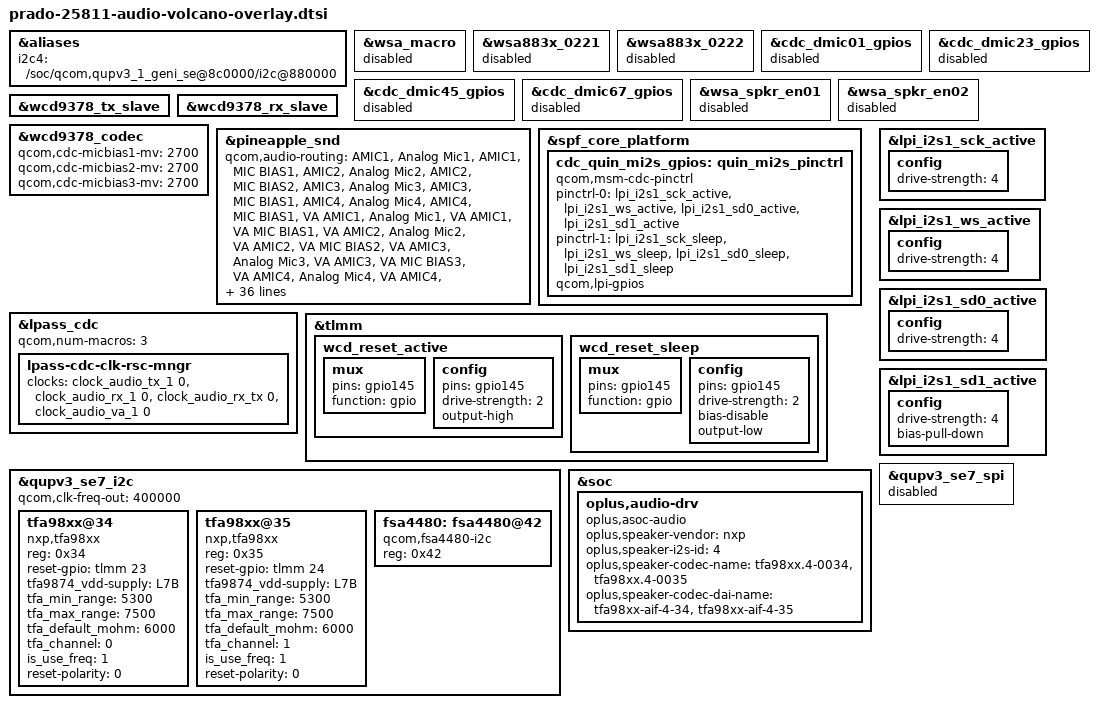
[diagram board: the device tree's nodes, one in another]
&aliases {
	i2c4 = "/soc/qcom,qupv3_1_geni_se@8c0000/i2c@880000";
};

&wsa_macro{
	status = "disabled";
};

&wsa883x_0221{
	status = "disabled";
};

&wsa883x_0222{
	status = "disabled";
};

&cdc_dmic01_gpios{
	status = "disabled";
};

&cdc_dmic23_gpios{
	status = "disabled";
};

&cdc_dmic45_gpios{
	status = "disabled";
};

&cdc_dmic67_gpios{
	status = "disabled";
};

&wsa_spkr_en01{
	status = "disabled";
};

&wsa_spkr_en02{
	status = "disabled";
};

&wcd9378_tx_slave{
	status = "okay";
};

&wcd9378_rx_slave{
	status = "okay";
};

&wcd9378_codec{
	status = "okay";
	qcom,cdc-micbias1-mv = <2700>;
	qcom,cdc-micbias2-mv = <2700>;
	qcom,cdc-micbias3-mv = <2700>;
};

&pineapple_snd{
    qcom,audio-routing =
		"AMIC1", "Analog Mic1",
		"AMIC1", "MIC BIAS1",
		"AMIC2", "Analog Mic2",
		"AMIC2", "MIC BIAS2",
		"AMIC3", "Analog Mic3",
		"AMIC3", "MIC BIAS1",
		"AMIC4", "Analog Mic4",
		"AMIC4", "MIC BIAS1",
		"VA AMIC1", "Analog Mic1",
		"VA AMIC1", "VA MIC BIAS1",
		"VA AMIC2", "Analog Mic2",
		"VA AMIC2", "VA MIC BIAS2",
		"VA AMIC3", "Analog Mic3",
		"VA AMIC3", "VA MIC BIAS3",
		"VA AMIC4", "Analog Mic4",
		"VA AMIC4", "VA MIC BIAS1",
		"TX DMIC0", "Digital Mic0",
		"TX DMIC0", "MIC BIAS3",
		"TX DMIC1", "Digital Mic1",
		"TX DMIC1", "MIC BIAS3",
		"TX DMIC2", "Digital Mic2",
		"TX DMIC2", "MIC BIAS1",
		"TX DMIC3", "Digital Mic3",
		"TX DMIC3", "MIC BIAS1",
		"IN1_HPHL", "HPHL_OUT",
		"IN2_HPHR", "HPHR_OUT",
		"IN3_AUX", "AUX_OUT",
		"RX_TX DEC0_INP", "TX DEC0 MUX",
		"RX_TX DEC1_INP", "TX DEC1 MUX",
		"RX_TX DEC2_INP", "TX DEC2 MUX",
		"RX_TX DEC3_INP", "TX DEC3 MUX",
		"VA SWR_INPUT", "VA_SWR_CLK",
		"VA_AIF1 CAP", "VA_SWR_CLK",
		"VA_AIF2 CAP", "VA_SWR_CLK",
		"VA_AIF3 CAP", "VA_SWR_CLK",
		"VA DMIC0", "Digital Mic0",
		"VA DMIC1", "Digital Mic1",
		"VA DMIC2", "Digital Mic2",
		"VA DMIC3", "Digital Mic3",
		"VA DMIC0", "VA MIC BIAS3",
		"VA DMIC1", "VA MIC BIAS3",
		"VA DMIC2", "VA MIC BIAS1",
		"VA DMIC3", "VA MIC BIAS1";
	asoc-codec  = <&stub_codec>, <&lpass_cdc>,
		<&wcd9378_codec>;
	asoc-codec-names = "msm-stub-codec.1", "lpass-cdc",
		"wcd9378_codec";
	qcom,wsa-max-devs = <0>;
	qcom,mi2s-audio-intf = <1>;
	qcom,tdm-audio-intf = <0>;
	qcom,quin-mi2s-gpios = <&cdc_quin_mi2s_gpios>;
	swr-haptics-unsupported; // disable qcom haptics
	qcom,wcn-bt = <1>;
	qcom,ext-disp-audio-rx = <1>;

	qcom,msm-mbhc-usbc-audio-supported = <1>;
	qcom,msm-mbhc-hs-mic-max-threshold-mv = <2600>;
	qcom,msm-mbhc-hs-mic-min-threshold-mv = <112>;/* 75*2700/1800 */
	qcom,msm-mbhc-hphl-swh = <0>;
	qcom,msm-mbhc-gnd-swh = <0>;
	oplus,mbhc-headset-micbias-alwayon = <1>;
	oplus,mbhc-check-cross-conn = <1>;

	fsa4480-i2c-handle = <&fsa4480>;
};

&spf_core_platform {
	cdc_quin_mi2s_gpios: quin_mi2s_pinctrl {
		status = "ok";
		compatible = "qcom,msm-cdc-pinctrl";
		pinctrl-names = "aud_active", "aud_sleep";
		pinctrl-0 = <&lpi_i2s1_sck_active &lpi_i2s1_ws_active
				&lpi_i2s1_sd0_active &lpi_i2s1_sd1_active>;
		pinctrl-1 = <&lpi_i2s1_sck_sleep &lpi_i2s1_ws_sleep
				&lpi_i2s1_sd0_sleep &lpi_i2s1_sd1_sleep>;
		qcom,lpi-gpios;
		#gpio-cells = <0>;
	};
};

&lpass_cdc {
	qcom,num-macros = <3>;
	lpass-cdc-clk-rsc-mngr {
		clock-names = "tx_core_clk", "rx_core_clk", "rx_tx_core_clk", "va_core_clk";
		clocks = <&clock_audio_tx_1 0>, <&clock_audio_rx_1 0>,
			<&clock_audio_rx_tx 0>, <&clock_audio_va_1 0>;
	};
};

&tlmm {
	/* WCD reset pin */
	wcd_reset_active: wcd_reset_active {
		mux {
			pins = "gpio145";
			function = "gpio";
		};

		config {
			pins = "gpio145";
			drive-strength = <2>;
			output-high;
		};
	};

	wcd_reset_sleep: wcd_reset_sleep {
		mux {
			pins = "gpio145";
			function = "gpio";
		};

		config {
			pins = "gpio145";
			drive-strength = <2>;
			bias-disable;
			output-low;
		};
	};
};

&qupv3_se7_i2c {
	status = "ok";
	qcom,clk-freq-out = <400000>;
	tfa98xx@34 {
		compatible = "nxp,tfa98xx";
		reg = <0x34>;
		reset-gpio = <&tlmm 23 0x00>;
		tfa9874_vdd-supply = <&L7B>;
		tfa_min_range = <5300>;
		tfa_max_range = <7500>;
		tfa_default_mohm = <6000>;
		tfa_channel = <0>;
		is_use_freq = <1>;
		reset-polarity = <0>;
		status = "ok";
	};
	tfa98xx@35 {
		compatible = "nxp,tfa98xx";
		reg = <0x35>;
		reset-gpio = <&tlmm 24 0x00>;
		tfa9874_vdd-supply = <&L7B>;
		tfa_min_range = <5300>;
		tfa_max_range = <7500>;
		tfa_default_mohm = <6000>;
		tfa_channel = <1>;
		is_use_freq = <1>;
		reset-polarity = <0>;
		status = "ok";
	};

	fsa4480: fsa4480@42 {
		status = "ok";
		compatible = "qcom,fsa4480-i2c";
		reg = <0x42>;
	};
};

&soc {
	oplus,audio-drv {
		compatible = "oplus,asoc-audio";
		//for nxp speaker
		oplus,speaker-vendor = "nxp";
		oplus,speaker-i2s-id = <4>;
		oplus,speaker-codec-name = "tfa98xx.4-0034", "tfa98xx.4-0035";
		oplus,speaker-codec-dai-name = "tfa98xx-aif-4-34", "tfa98xx-aif-4-35";
	};
};

&lpi_i2s1_sck_active {
	config {
		drive-strength = <4>;   /* 4 mA */
	};
};

&lpi_i2s1_ws_active {
	config {
		drive-strength = <4>;   /* 4 mA */
	};
};

&lpi_i2s1_sd0_active {
	config {
		drive-strength = <4>;   /* 4 mA */
	};
};

&lpi_i2s1_sd1_active {
	config {
		drive-strength = <4>;   /* 4 mA */
		bias-pull-down;
	};
};

&qupv3_se7_spi {
	status = "disable";
};
